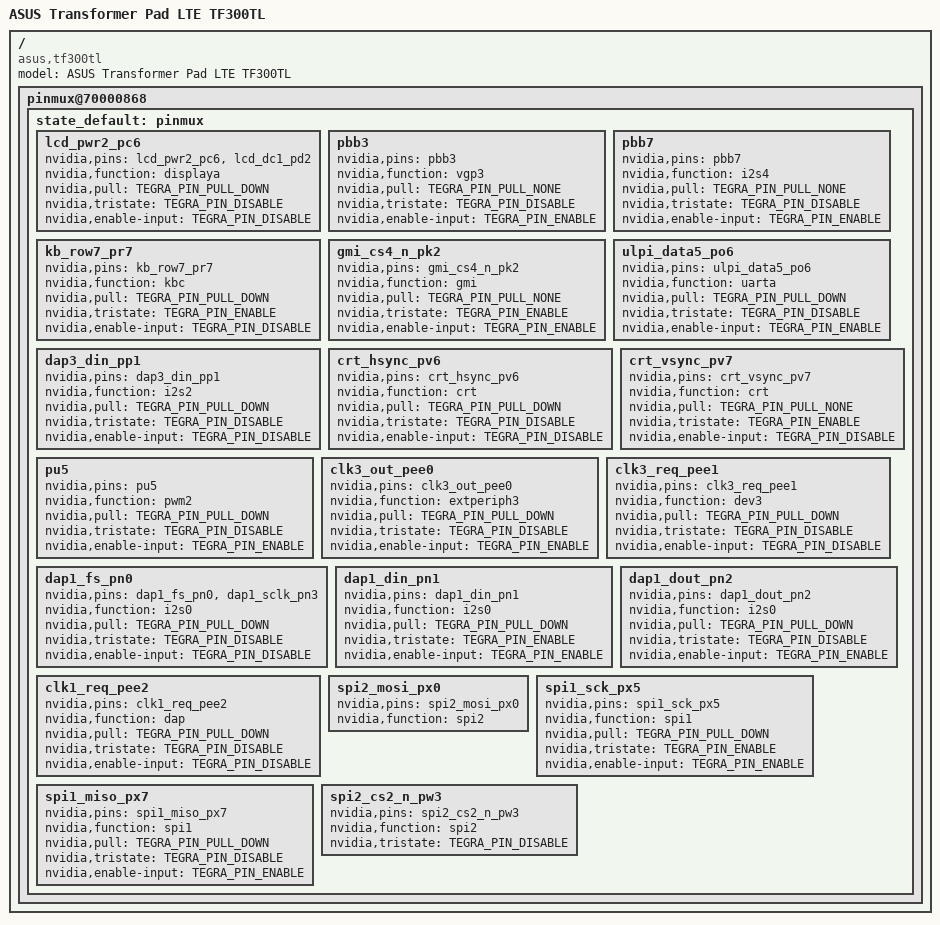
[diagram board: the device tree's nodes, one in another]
// SPDX-License-Identifier: GPL-2.0
/dts-v1/;

#include "tegra30-asus-transformer.dtsi"

/ {
	model = "ASUS Transformer Pad LTE TF300TL";
	compatible = "asus,tf300tl", "nvidia,tegra30";

	pinmux@70000868 {
		state_default: pinmux {
			lcd_pwr2_pc6 {
				nvidia,pins = "lcd_pwr2_pc6",
						"lcd_dc1_pd2";
				nvidia,function = "displaya";
				nvidia,pull = <TEGRA_PIN_PULL_DOWN>;
				nvidia,tristate = <TEGRA_PIN_DISABLE>;
				nvidia,enable-input = <TEGRA_PIN_DISABLE>;
			};

			pbb3 {
				nvidia,pins = "pbb3";
				nvidia,function = "vgp3";
				nvidia,pull = <TEGRA_PIN_PULL_NONE>;
				nvidia,tristate = <TEGRA_PIN_DISABLE>;
				nvidia,enable-input = <TEGRA_PIN_ENABLE>;
			};

			pbb7 {
				nvidia,pins = "pbb7";
				nvidia,function = "i2s4";
				nvidia,pull = <TEGRA_PIN_PULL_NONE>;
				nvidia,tristate = <TEGRA_PIN_DISABLE>;
				nvidia,enable-input = <TEGRA_PIN_ENABLE>;
			};

			kb_row7_pr7 {
				nvidia,pins = "kb_row7_pr7";
				nvidia,function = "kbc";
				nvidia,pull = <TEGRA_PIN_PULL_DOWN>;
				nvidia,tristate = <TEGRA_PIN_ENABLE>;
				nvidia,enable-input = <TEGRA_PIN_DISABLE>;
			};

			gmi_cs4_n_pk2 {
				nvidia,pins = "gmi_cs4_n_pk2";
				nvidia,function = "gmi";
				nvidia,pull = <TEGRA_PIN_PULL_NONE>;
				nvidia,tristate = <TEGRA_PIN_ENABLE>;
				nvidia,enable-input = <TEGRA_PIN_ENABLE>;
			};

			/* TF300TL specific pinmux reconfiguration */

			ulpi_data5_po6 {
				nvidia,pins = "ulpi_data5_po6";
				nvidia,function = "uarta";
				nvidia,pull = <TEGRA_PIN_PULL_DOWN>;
				nvidia,tristate = <TEGRA_PIN_DISABLE>;
				nvidia,enable-input = <TEGRA_PIN_ENABLE>;
			};

			dap3_din_pp1 {
				nvidia,pins = "dap3_din_pp1";
				nvidia,function = "i2s2";
				nvidia,pull = <TEGRA_PIN_PULL_DOWN>;
				nvidia,tristate = <TEGRA_PIN_DISABLE>;
				nvidia,enable-input = <TEGRA_PIN_DISABLE>;
			};

			crt_hsync_pv6 {
				nvidia,pins = "crt_hsync_pv6";
				nvidia,function = "crt";
				nvidia,pull = <TEGRA_PIN_PULL_DOWN>;
				nvidia,tristate = <TEGRA_PIN_DISABLE>;
				nvidia,enable-input = <TEGRA_PIN_DISABLE>;
			};

			crt_vsync_pv7 {
				nvidia,pins = "crt_vsync_pv7";
				nvidia,function = "crt";
				nvidia,pull = <TEGRA_PIN_PULL_NONE>;
				nvidia,tristate = <TEGRA_PIN_ENABLE>;
				nvidia,enable-input = <TEGRA_PIN_DISABLE>;
			};

			pu5 {
				nvidia,pins = "pu5";
				nvidia,function = "pwm2";
				nvidia,pull = <TEGRA_PIN_PULL_DOWN>;
				nvidia,tristate = <TEGRA_PIN_DISABLE>;
				nvidia,enable-input = <TEGRA_PIN_ENABLE>;
			};

			clk3_out_pee0 {
				nvidia,pins = "clk3_out_pee0";
				nvidia,function = "extperiph3";
				nvidia,pull = <TEGRA_PIN_PULL_DOWN>;
				nvidia,tristate = <TEGRA_PIN_DISABLE>;
				nvidia,enable-input = <TEGRA_PIN_ENABLE>;
			};

			clk3_req_pee1 {
				nvidia,pins = "clk3_req_pee1";
				nvidia,function = "dev3";
				nvidia,pull = <TEGRA_PIN_PULL_DOWN>;
				nvidia,tristate = <TEGRA_PIN_DISABLE>;
				nvidia,enable-input = <TEGRA_PIN_DISABLE>;
			};

			dap1_fs_pn0 {
				nvidia,pins = "dap1_fs_pn0",
						"dap1_sclk_pn3";
				nvidia,function = "i2s0";
				nvidia,pull = <TEGRA_PIN_PULL_DOWN>;
				nvidia,tristate = <TEGRA_PIN_DISABLE>;
				nvidia,enable-input = <TEGRA_PIN_DISABLE>;
			};

			dap1_din_pn1 {
				nvidia,pins = "dap1_din_pn1";
				nvidia,function = "i2s0";
				nvidia,pull = <TEGRA_PIN_PULL_DOWN>;
				nvidia,tristate = <TEGRA_PIN_ENABLE>;
				nvidia,enable-input = <TEGRA_PIN_ENABLE>;
			};

			dap1_dout_pn2 {
				nvidia,pins = "dap1_dout_pn2";
				nvidia,function = "i2s0";
				nvidia,pull = <TEGRA_PIN_PULL_DOWN>;
				nvidia,tristate = <TEGRA_PIN_DISABLE>;
				nvidia,enable-input = <TEGRA_PIN_ENABLE>;
			};

			clk1_req_pee2 {
				nvidia,pins = "clk1_req_pee2";
				nvidia,function = "dap";
				nvidia,pull = <TEGRA_PIN_PULL_DOWN>;
				nvidia,tristate = <TEGRA_PIN_DISABLE>;
				nvidia,enable-input = <TEGRA_PIN_DISABLE>;
			};

			spi2_mosi_px0 {
				nvidia,pins = "spi2_mosi_px0";
				nvidia,function = "spi2";
			};

			spi1_sck_px5 {
				nvidia,pins = "spi1_sck_px5";
				nvidia,function = "spi1";
				nvidia,pull = <TEGRA_PIN_PULL_DOWN>;
				nvidia,tristate = <TEGRA_PIN_ENABLE>;
				nvidia,enable-input = <TEGRA_PIN_ENABLE>;
			};

			spi1_miso_px7 {
				nvidia,pins = "spi1_miso_px7";
				nvidia,function = "spi1";
				nvidia,pull = <TEGRA_PIN_PULL_DOWN>;
				nvidia,tristate = <TEGRA_PIN_DISABLE>;
				nvidia,enable-input = <TEGRA_PIN_ENABLE>;
			};

			spi2_cs2_n_pw3 {
				nvidia,pins = "spi2_cs2_n_pw3";
				nvidia,function = "spi2";
				nvidia,tristate = <TEGRA_PIN_DISABLE>;
			};
		};
	};
};
